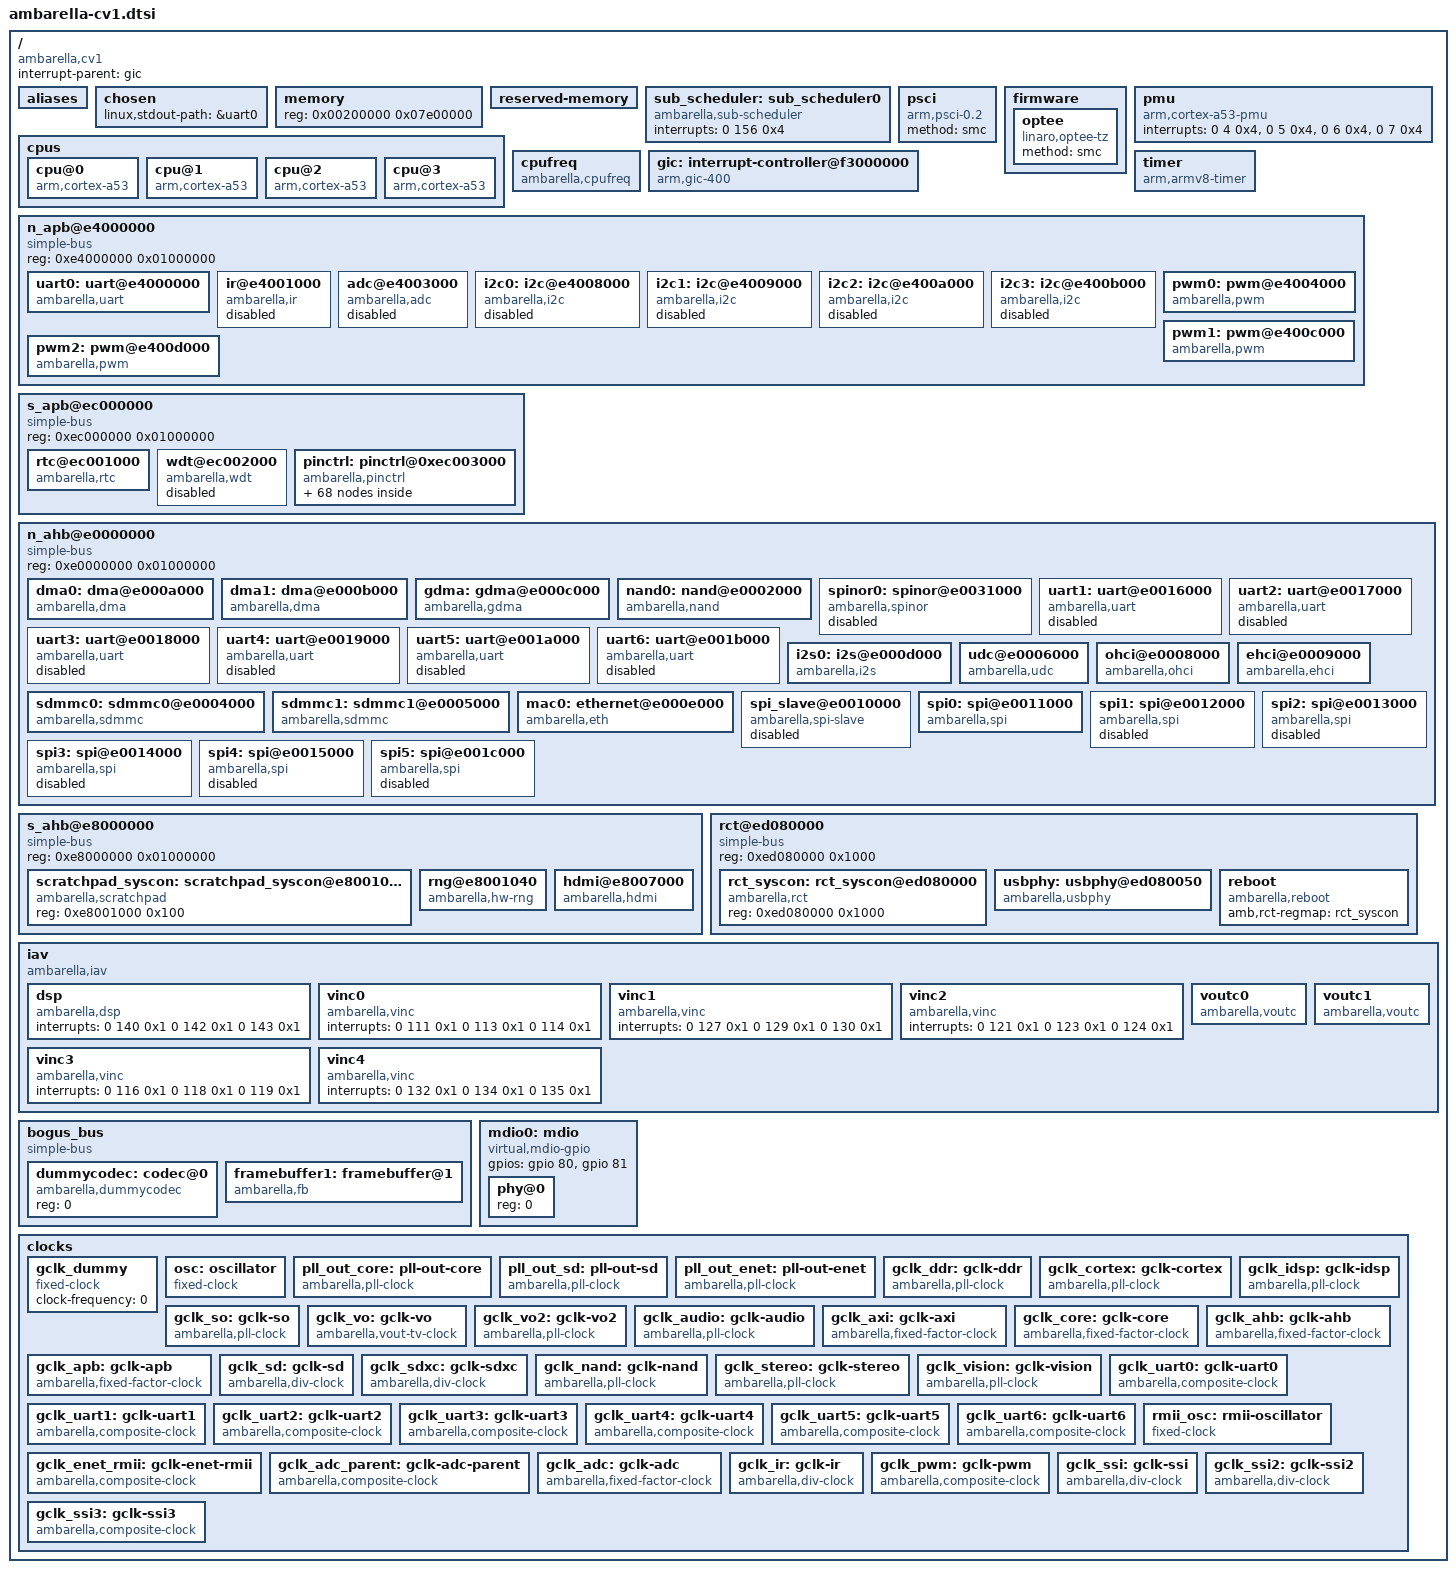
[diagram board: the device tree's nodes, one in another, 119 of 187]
/*
 * Copyright (C) 2013 Ambarella,Inc. - http://www.ambarella.com/
 * Author: Cao Rongrong <rrcao@ambarella.com>
 *
 * This program is free software; you can redistribute it and/or modify
 * it under the terms of the GNU General Public License version 2 as
 * published by the Free Software Foundation.
 */

/ {
	compatible = "ambarella,cv1";
	interrupt-parent = <&gic>;
	#address-cells = <1>;
	#size-cells = <1>;

	aliases {
		serial0 = &uart0;
		serial1 = &uart1;
		serial2 = &uart2;
		serial3 = &uart3;
		serial4 = &uart4;
		serial5 = &uart5;
		serial6 = &uart6;
		nand = &nand0;
		sd0 = &sdmmc0;
		spinor = &spinor0;
		i2c0 = &i2c0;
		i2c1 = &i2c1;
		i2c2 = &i2c2;
		i2c3 = &i2c3;
		spi0 = &spi0;
		spi1 = &spi1;
		spi2 = &spi2;
		ethernet0 = &mac0;
		mdio-gpio0 = &mdio0;
	};

	chosen {
		linux,stdout-path = &uart0;
	};

	/*
	 * the memory node will be overwritten in Amboot,
	 * here is just the default value.
	 */
	memory {
		device_type = "memory";
		reg = <0x00200000 0x07e00000>; /* 126M */
	};

	reserved-memory {
		#address-cells = <1>;
		#size-cells = <1>;
		ranges;
	};

	sub_scheduler: sub_scheduler0 {
		compatible = "ambarella,sub-scheduler";
		interrupts = <0 156 0x4>;
	};

	psci {
		compatible = "arm,psci-0.2";
		method = "smc";
	};

	firmware {
		optee {
			compatible = "linaro,optee-tz";
			method = "smc";
		};
	};

	pmu {
		compatible = "arm,cortex-a53-pmu";
		interrupts = <0 4 0x4>,
			     <0 5 0x4>,
			     <0 6 0x4>,
			     <0 7 0x4>;
	};

	cpus {
		#address-cells = <1>;
		#size-cells = <0>;
		cpu@0 {
			compatible = "arm,cortex-a53", "arm,armv8";
			device_type = "cpu";
			reg = <0x0>;
			enable-method = "psci";
		};

		cpu@1 {
			compatible = "arm,cortex-a53", "arm,armv8";
			device_type = "cpu";
			reg = <0x1>;
			enable-method = "psci";
		};

		cpu@2 {
			compatible = "arm,cortex-a53", "arm,armv8";
			device_type = "cpu";
			reg = <0x2>;
			enable-method = "psci";
		};

		cpu@3 {
			compatible = "arm,cortex-a53", "arm,armv8";
			device_type = "cpu";
			reg = <0x3>;
			enable-method = "psci";
		};
	};

	cpufreq {
		compatible = "ambarella,cpufreq";
		/*
		 * Config effective clocks. '%KHZ'
		 *
		 * 0 - cortex.
		 * 1 - pll_out_core.
		 * 2 - cortex and pll_out_core.
		 */
		cpufreq-effective-clock = <0>;			/* default 'cortex' */
		clocks = <&gclk_cortex &pll_out_core>;
		clock-names = "cortex_clk", "core_clk";
		clocks-frequency-cortex-core =
			<1008000  672000>,
			< 816000  504000>,
			< 600000  336000>;
	};

	gic: interrupt-controller@f3000000 {
		compatible = "arm,gic-400";
		#interrupt-cells = <3>;
		#address-cells = <0>;
		interrupt-controller;
		reg = <0xf3001000 0x1000>,	/* GIC Dist */
		      <0xf3002000 0x2000>,	/* GIC CPU */
		      /* following are not used if no virtulization */
		      <0xf3004000 0x2000>,	/* GIC VCPU Control */
		      <0xf3006000 0x2000>;	/* GIC VCPU */
		interrupts = <1 9 0xf04>;	/* GIC Maintenence IRQ */
	};

	timer {
		compatible = "arm,armv8-timer";
		interrupts = <1 13 0xf08>,	/* Secure Phys IRQ */
			     <1 14 0xf08>,	/* Non-secure Phys IRQ */
			     <1 11 0xf08>,	/* Virt IRQ */
			     <1 10 0xf08>;	/* Hyp IRQ */
	};

	n_apb@e4000000 { /* Non-Secure APB */
		compatible = "simple-bus";
		#address-cells = <1>;
		#size-cells = <1>;
		reg = <0xe4000000 0x01000000>;
		ranges;

		uart0: uart@e4000000 {
			compatible = "ambarella,uart";
			reg = <0xe4000000 0x1000>;
			interrupts = <0 22 0x4>;
			pinctrl-names = "default";
			pinctrl-0 = <&uart0_pins>;
			clocks = <&gclk_uart0>;
			status = "ok";
		};

		ir@e4001000 {
			compatible = "ambarella,ir";
			reg = <0xe4001000 0x1000>;
			interrupts = <0 21 0x4>;
			pinctrl-names = "default";
			pinctrl-0 = <&ir_pins>;
			clocks = <&gclk_ir>;
			status = "disabled";
		};

		adc@e4003000 {
			compatible = "ambarella,adc";
			#io-channel-cells = <1>;
			reg = <0xe4003000 0x1000>;
			interrupts = <0 14 0x4>;
			clock-frequency = <3000000>;
			clocks = <&gclk_adc>;
			amb,rct-regmap = <&rct_syscon>;
			amb,scaler-1v8 = <0x01>;
			amb,t2v-channel = <2>;
			status = "disabled";
		};

		i2c0: i2c@e4008000 {
			compatible = "ambarella,i2c";
			#address-cells = <1>;
			#size-cells = <0>;
			reg = <0xe4008000 0x1000>;
			interrupts = <0 16 0x4>;
			pinctrl-names = "default";
			pinctrl-0 = <&i2c0_pins_a>;
			clocks = <&gclk_apb>;
			clock-frequency = <100000>;
			amb,i2c-class = <0x81>;
			status = "disabled";
		};

		i2c1: i2c@e4009000 {
			compatible = "ambarella,i2c";
			#address-cells = <1>;
			#size-cells = <0>;
			reg = <0xe4009000 0x1000>;
			interrupts = <0 17 0x4>;
			pinctrl-names = "default";
			pinctrl-0 = <&i2c1_pins_a>;
			clocks = <&gclk_apb>;
			clock-frequency = <100000>;
			amb,i2c-class = <0x08>;
			status = "disabled";
		};

		i2c2: i2c@e400a000 {
			compatible = "ambarella,i2c";
			#address-cells = <1>;
			#size-cells = <0>;
			reg = <0xe400a000 0x1000>;
			interrupts = <0 18 0x4>;
			clocks = <&gclk_apb>;
			pinctrl-names = "default";
			pinctrl-0 = <&i2c2_pins_a>;
			clock-frequency = <100000>;
			amb,i2c-class = <0x81>;
			status = "disabled";
		};

		i2c3: i2c@e400b000 {
			compatible = "ambarella,i2c";
			#address-cells = <1>;
			#size-cells = <0>;
			reg = <0xe400b000 0x1000>;
			interrupts = <0 19 0x4>;
			clocks = <&gclk_apb>;
			pinctrl-names = "default";
			pinctrl-0 = <&i2c3_pins_a>;
			clock-frequency = <100000>;
			amb,i2c-class = <0x81>;
			status = "disabled";
		};

		pwm0: pwm@e4004000 {
			compatible = "ambarella,pwm";
			reg = <0xe4004000 0x1000>;
			clock-frequency = <2000000>;
			clocks = <&gclk_pwm>;
			#pwm-cells = <3>;
		};

		pwm1: pwm@e400c000 {
			compatible = "ambarella,pwm";
			reg = <0xe400c000 0x1000>;
			clock-frequency = <2000000>;
			clocks = <&gclk_pwm>;
			#pwm-cells = <3>;
		};

		pwm2: pwm@e400d000 {
			compatible = "ambarella,pwm";
			reg = <0xe400d000 0x1000>;
			clock-frequency = <2000000>;
			clocks = <&gclk_pwm>;
			#pwm-cells = <3>;
		};
	};

	s_apb@ec000000 { /* Secure APB */
		compatible = "simple-bus";
		#address-cells = <1>;
		#size-cells = <1>;
		reg = <0xec000000 0x01000000>;
		ranges;

		rtc@ec001000 {
			compatible = "ambarella,rtc";
			reg = <0xec001000 0x1000>;
			interrupts = <0 160 0x1>;
		};

		wdt@ec002000 {
			compatible = "ambarella,wdt";
			reg = <0xec002000 0x1000>;
			amb,rct-regmap = <&rct_syscon>;
			/* interrupts = <0 43 0x4>; */
			timeout-sec = <15>;
			status = "disabled";
		};

		pinctrl: pinctrl@0xec003000 {
			compatible = "ambarella,pinctrl", "simple-bus";
			#address-cells = <1>;
			#size-cells = <0>;
			reg = <0xec003000 0x1000>,
			      <0xec004000 0x1000>,
			      <0xec005000 0x1000>,
			      <0xec006000 0x1000>,
			      <0xec007000 0x1000>,
			      <0xec008000 0x1000>,
			      <0xec009000 0x1000>,
			      <0xec000000 0x1000>,
			      <0xec001080 0x100>,
			      <0xed080314 0x13c>;
			reg-names = "gpio0", "gpio1", "gpio2", "gpio3",
				    "gpio4", "gpio5", "gpio6","iomux",
				    "pad", "ds";
			#gpio-range-cells = <3>;

			gpio: gpio@0 {
				compatible = "ambarella,gpio";
				reg = <0>;
				/* gpio interrupts to gic */
				interrupts = <0 44 0x4>,
					     <0 45 0x4>,
					     <0 46 0x4>,
					     <0 47 0x4>,
					     <0 48 0x4>,
					     <0 49 0x4>,
					     <0 50 0x4>;
				gpio-controller;
				#gpio-cells = <2>;
				gpio-ranges = <&pinctrl 0 0 224>;
				interrupt-controller;
				#interrupt-cells = <2>;
			};

			uart0_pins: uart0@0 {
				reg = <0>;
				amb,pinmux-ids = <0x1033 0x1034>;
			};

			uart1_pins: uart1@0 {
				reg = <0>;
				amb,pinmux-ids = <0x10ba 0x10bb>;
			};

			uart1_flow_pins: uart1_flow@0 {
				reg = <0>;
				amb,pinmux-ids = <0x10bc 0x10bd>;
			};

			uart2_pins: uart2@0 {
				reg = <0>;
				amb,pinmux-ids = <0x10be 0x10bf>;
			};

			uart2_flow_pins: uart2_flow@0 {
				reg = <0>;
				amb,pinmux-ids = <0x10c0 0x10c1>;
			};

			uart3_pins: uart3@0 {
				reg = <0>;
				amb,pinmux-ids = <0x10c2 0x10c3>;
			};

			uart3_flow_pins: uart3_flow@0 {
				reg = <0>;
				amb,pinmux-ids = <0x10c4 0x10c5>;
			};

			uart4_pins: uart4@0 {
				reg = <0>;
				amb,pinmux-ids = <0x10c6 0x10c7>;
			};

			uart4_flow_pins: uart4_flow@0 {
				reg = <0>;
				amb,pinmux-ids = <0x10c8 0x10c9>;
			};

			uart5_pins: uart5@0 {
				reg = <0>;
				amb,pinmux-ids = <0x10ca 0x10cc>;
			};

			uart5_flow_pins: uart5_flow@0 {
				reg = <0>;
				amb,pinmux-ids = <0x10ce 0x10d0>;
			};

			uart6_pins: uart6@0 {
				reg = <0>;
				amb,pinmux-ids = <0x10cb 0x10cd>;
			};

			uart6_flow_pins: uart6_flow@0 {
				reg = <0>;
				amb,pinmux-ids = <0x10cf 0x10d1>;
			};

			nand0_pins: nand0@0 {
				reg = <0>;
				amb,pinmux-ids = <0x2056 0x2057 0x2058 0x205d
						  0x205e 0x205f 0x2060 0x2061
						  0x2062 0x2063 0x2064 0x2065
						  0x2066 0x2067 0x2068>;
			};

			snand0_pins: snand0@0 {
				reg = <0>;
				amb,pinmux-ids = <0x405d 0x405e 0x4064 0x4065
						  0x4066 0x4067>;
			};

			spinor0_pins: spinor0@0 {
				reg = <0>;
				amb,pinmux-ids = <0x3057 0x3058 0x305d 0x305e
						  0x305f 0x3060 0x3061 0x3062
						  0x3063 0x3064 0x3065 0x3066
						  0x3067>;
			};

			sdmmc0_cd_pin: sdmmc0_cd@0 {
				reg = <0>;
				amb,pinmux-ids = <0x205b>;
			};

			sdmmc0_wp_pin: sdmmc0_wp@0 {
				reg = <0>;
				amb,pinmux-ids = <0x205c>;
			};

			sdmmc0_reset_pin: sdmmc0_reset@0 {
				reg = <0>;
				amb,pinmux-ids = <0x207d>;
			};

			sdmmc0_pins_1bit: sdmmc0@0 {
				reg = <0>;
				amb,pinmux-ids = <0x2059 0x205a 0x2069>;
			};

			sdmmc0_pins_4bit: sdmmc0@1 {
				reg = <1>;
				amb,pinmux-ids = <0x2059 0x205a 0x2069 0x206a
						  0x206b 0x206c>;
			};

			sdmmc0_pins_8bit: sdmmc0@2 {
				reg = <2>;
				amb,pinmux-ids = <0x2059 0x205a 0x2069 0x206a
						  0x206b 0x206c 0x206d 0x206e
						  0x206f 0x2070>;
			};

			sdmmc1_cd_pin: sdmmc1_cd@0 {
				reg = <0>;
				amb,pinmux-ids = <0x2077>;
			};

			sdmmc1_wp_pin: sdmmc1_wp@0 {
				reg = <0>;
				amb,pinmux-ids = <0x2078>;
			};

			sdmmc1_reset_pin: sdmmc1_reset@0 {
				reg = <0>;
				amb,pinmux-ids = <0x207e>;
			};

			sdmmc1_pins_1bit: sdmmc1@0 {
				reg = <0>;
				amb,pinmux-ids = <0x2071 0x2072 0x2073>;
			};

			sdmmc1_pins_4bit: sdmmc1@1 {
				reg = <1>;
				amb,pinmux-ids = <0x2071 0x2072 0x2073 0x2074
						  0x2075 0x2076>;
			};

			sdmmc1_pins_8bit: sdmmc1@2 {
				reg = <2>;
				amb,pinmux-ids = <0x2071 0x2072 0x2073 0x2074
						  0x2075 0x2076 0x2079 0x207a
						  0x207b 0x207c>;
			};

			rgmii_pins: eth0@0 {
				reg = <0>;
				amb,pinmux-ids = <0x4046 0x4047 0x4048 0x4049
						  0x404a 0x404b 0x404c 0x404d
						  0x404e 0x404f 0x4052 0x4053
						  0x4054 0x4055>;
			};

			rmii_pins: eth0@1 {
				reg = <1>;
				amb,pinmux-ids = <0x3046 0x3047 0x3048 0x304b
						  0x304c 0x304f 0x3052 0x3053
						  0x3054 0x3055>;
			};

			rgmii_mdio_pins: mdio@0 {
				reg = <0>;
				amb,pinmux-ids = <0x4050 0x4051>;
			};

			rmii_mdio_pins: mdio@1 {
				reg = <1>;
				amb,pinmux-ids = <0x3050 0x3051>;
			};

			i2c0_pins_a: i2c0@0 {
				reg = <0>;
				amb,pinmux-ids = <0x100f 0x1010>;
			};

			i2c0_pins_b: i2c0@1 {
				reg = <1>;
				amb,pinmux-ids = <0x2025 0x2026>;
			};

			i2c1_pins_a: i2c1@0 {
				reg = <0>;
				amb,pinmux-ids = <0x1011 0x1012>;
			};

			i2c1_pins_b: i2c1@1 {
				reg = <1>;
				amb,pinmux-ids = <0x2027 0x2028>;
			};

			i2c2_pins_a: i2c2@0 {
				reg = <0>;
				amb,pinmux-ids = <0x1013 0x1014>;
			};

			i2c2_pins_b: i2c2@1 {
				reg = <1>;
				amb,pinmux-ids = <0x2029 0x202a>;
			};

			i2c3_pins_a: i2c3@0 {
				reg = <0>;
				amb,pinmux-ids = <0x1015 0x1016>;
			};

			i2c3_pins_b: i2c3@1 {
				reg = <1>;
				amb,pinmux-ids = <0x202b 0x202c>;
			};

			ir_pins: ir0@0 {
				reg = <0>;
				amb,pinmux-ids = <0x1019>;
			};

			i2s0_pins: i2s0@0 {
				reg = <0>;
				amb,pinmux-ids = <0x1041 0x1042 0x1043 0x1044
						  0x1045>;
			};

			usb_host0_pins_a: uhc0@0 { /* USB0: host/device configurable */
				reg = <0>;
				amb,pinmux-ids = <0x3008 0x300a>;
			};

			usb_host0_pins_b: uhc0@1 { /* USB0: host/device configurable */
				reg = <1>;
				amb,pinmux-ids = <0x302f 0x3031>;
			};

			usb_host0_pins_c: uhc0@2 { /* USB0: host/device configurable */
				reg = <2>;
				amb,pinmux-ids = <0x5079 0x507b>;
			};

			pwm0_pins_a: pwm0@0 {
				reg = <0>;
				amb,pinmux-ids = <0x1035>;
			};

			pwm0_pins_b: pwm0@1 {
				reg = <1>;
				amb,pinmux-ids = <0x10b9>;
			};

			pwm1_pins: pwm1@0 {
				reg = <0>;
				amb,pinmux-ids = <0x3036>;
			};

			pwm2_pins: pwm2@0 {
				reg = <0>;
				amb,pinmux-ids = <0x3037>;
			};

			pwm3_pins: pwm3@0 {
				reg = <0>;
				amb,pinmux-ids = <0x3038>;
			};

			pwm4_pins: pwm4@0 {
				reg = <0>;
				amb,pinmux-ids = <0x1039>;
			};

			pwm5_pins: pwm5@0 {
				reg = <0>;
				amb,pinmux-ids = <0x103a>;
			};

			pwm6_pins: pwm6@0 {
				reg = <0>;
				amb,pinmux-ids = <0x103b>;
			};

			pwm7_pins: pwm7@0 {
				reg = <0>;
				amb,pinmux-ids = <0x103c>;
			};

			pwm8_pins: pwm8@0 {
				reg = <0>;
				amb,pinmux-ids = <0x103d>;
			};

			pwm9_pins: pwm9@0 {
				reg = <0>;
				amb,pinmux-ids = <0x103e>;
			};

			pwm10_pins: pwm10@0 {
				reg = <0>;
				amb,pinmux-ids = <0x103f>;
			};

			pwm11_pins: pwm11@0 {
				reg = <0>;
				amb,pinmux-ids = <0x1040>;
			};

			spi_slave_pins: spi_slave@0 {
				reg = <0>;
				amb,pinmux-ids = <0x102f 0x1030 0x1031 0x1032>;
			};

			spi0_pins: spi0@0 {
				reg = <0>;
				amb,pinmux-ids = <0x101a 0x101b 0x101c>;
			};

			spi1_pins_a: spi1@0 {
				reg = <0>;
				amb,pinmux-ids = <0x2000 0x2001 0x2002>;
			};

			spi1_pins_b: spi1@1 {
				reg = <1>;
				amb,pinmux-ids = <0x202f 0x2030 0x2031>;
			};

			spi1_pins_c: spi1@2 {
				reg = <2>;
				amb,pinmux-ids = <0x20ba 0x20bb 0x20bc>;
			};

			spi2_pins: spi2@0 {
				reg = <0>;
				amb,pinmux-ids = <0x101f 0x1020 0x1021>;
			};

			spi3_pins: spi3@0 {
				reg = <0>;
				amb,pinmux-ids = <0x1023 0x1024 0x1025>;
			};

			spi4_pins: spi4@0 {
				reg = <0>;
				amb,pinmux-ids = <0x1027 0x1028 0x1029>;
			};

			spi5_pins: spi5@0 {
				reg = <0>;
				amb,pinmux-ids = <0x102b 0x102c 0x102d>;
			};
		};
	};

	n_ahb@e0000000 { /* Non-Secure AHB */
		compatible = "simple-bus";
		#address-cells = <1>;
		#size-cells = <1>;
		reg = <0xe0000000 0x01000000>;
		ranges;

		dma0: dma@e000a000 {
			compatible = "ambarella,dma";
			reg = <0xe000a000 0x1000>, <0xe8001030 0x8>;
			interrupts = <0 83 0x4>;
			#dma-cells = <1>;
			dma-channels = <8>;
			dma-requests = <30>;
		};

		dma1: dma@e000b000 {
			compatible = "ambarella,dma";
			reg = <0xe000b000 0x1000>, <0xe8001038 0x8>;
			interrupts = <0 84 0x4>;
			#dma-cells = <1>;
			dma-channels = <8>;
			dma-requests = <30>;
		};

		gdma: gdma@e000c000 {
			compatible = "ambarella,gdma";
			reg = <0xe000c000 0x400>;
			interrupts = <0 70 0x1>;
		};

		nand0: nand@e0002000 {
			compatible = "ambarella,nand";
			#address-cells = <1>;
			#size-cells = <1>;
			reg = <0xe0002000 0x1000>;
			interrupts = <0 68 0x4>;	/* fio_irq */
			amb,rct-regmap = <&rct_syscon>;
			pinctrl-names = "default", "spinand";
			pinctrl-0 = <&nand0_pins>;
			pinctrl-1 = <&snand0_pins>;
			clocks = <&gclk_nand>;
			nand-on-flash-bbt;
			/* amb,soft-ecc = <1>; */
		};

		spinor0: spinor@e0031000 {
			compatible = "ambarella,spinor";
			reg = <0xe0031000 0x2ff>; /* spi nor controller */
			interrupts = <0 73 0x4>;
			pinctrl-names = "default";
			pinctrl-0 = <&spinor0_pins>;
			clocks = <&gclk_ssi3>;
			dmas = <&dma0 4>, <&dma0 5>;
			dma-names = "tx", "rx";
			max-frequency = <50000000>;
			status = "disabled";
		};

		uart1: uart@e0016000 {
			compatible = "ambarella,uart";
			reg = <0xe0016000 0x1000>;
			interrupts = <0 59 0x4>;
			pinctrl-names = "default";
			pinctrl-0 = <&uart1_pins &uart1_flow_pins>;
			clocks = <&gclk_uart1>;
			status = "disabled";
			amb,msr-used;	/* use Modem Status Register */
			amb,txdma-used;
			amb,rxdma-used;
			dmas = <&dma0 8>, <&dma0 9>;
			dma-names = "tx", "rx";
		};

		uart2: uart@e0017000 {
			compatible = "ambarella,uart";
			reg = <0xe0017000 0x1000>;
			interrupts = <0 60 0x4>;
			pinctrl-names = "default";
			pinctrl-0 = <&uart2_pins &uart2_flow_pins>;
			clocks = <&gclk_uart2>;
			amb,msr-used;	/* use Modem Status Register */
			amb,txdma-used;
			amb,rxdma-used;
			dmas = <&dma1 12>, <&dma1 13>;
			dma-names = "tx", "rx";
			status = "disabled";
		};

		uart3: uart@e0018000 {
			compatible = "ambarella,uart";
			reg = <0xe0018000 0x1000>;
			interrupts = <0 61 0x4>;
			pinctrl-names = "default";
			pinctrl-0 = <&uart3_pins &uart3_flow_pins>;
			clocks = <&gclk_uart3>;
			amb,msr-used;	/* use Modem Status Register */
			amb,txdma-used;
			amb,rxdma-used;
			dmas = <&dma1 14>, <&dma1 15>;
			dma-names = "tx", "rx";
			status = "disabled";
		};

		uart4: uart@e0019000 {
			compatible = "ambarella,uart";
			reg = <0xe0019000 0x1000>;
			interrupts = <0 62 0x4>;
			pinctrl-names = "default";
			pinctrl-0 = <&uart4_pins &uart4_flow_pins>;
			clocks = <&gclk_uart4>;
			amb,msr-used;	/* use Modem Status Register */
			amb,txdma-used;
			amb,rxdma-used;
			dmas = <&dma1 16>, <&dma1 17>;
			dma-names = "tx", "rx";
			status = "disabled";
		};

		uart5: uart@e001a000 {
			compatible = "ambarella,uart";
			reg = <0xe001a000 0x1000>;
			interrupts = <0 63 0x4>;
			pinctrl-names = "default";
			pinctrl-0 = <&uart5_pins &uart5_flow_pins>;
			clocks = <&gclk_uart5>;
			amb,msr-used;	/* use Modem Status Register */
			amb,txdma-used;
			amb,rxdma-used;
			dmas = <&dma1 18>, <&dma1 19>;
			dma-names = "tx", "rx";
			status = "disabled";
		};

		uart6: uart@e001b000 {
			compatible = "ambarella,uart";
			reg = <0xe001b000 0x1000>;
			interrupts = <0 64 0x4>;
			pinctrl-names = "default";
			pinctrl-0 = <&uart6_pins &uart6_flow_pins>;
			clocks = <&gclk_uart6>;
			amb,msr-used;	/* use Modem Status Register */
			amb,txdma-used;
			amb,rxdma-used;
			dmas = <&dma1 20>, <&dma1 21>;
			dma-names = "tx", "rx";
			status = "disabled";
		};

		i2s0: i2s@e000d000 {
			compatible = "ambarella,i2s";
			#sound-dai-cells = <0>;
			reg = <0xe000d000 0x1000>;
			pinctrl-names = "default";
			pinctrl-0 = <&i2s0_pins>;
			clocks = <&gclk_audio>;
			amb,i2s-channels = <2>;
			amb,default-mclk = <12288000>;
			dmas = <&dma0 10>, <&dma0 11>;
			dma-names = "tx", "rx";
		};

		udc@e0006000 {
			compatible = "ambarella,udc";
			reg = <0xe0006000 0x2000>;
			interrupts = <0 67 0x4>;
			amb,rct-regmap = <&rct_syscon>;
			amb,scr-regmap = <&scratchpad_syscon>;
			amb,usbphy = <&usbphy>;
		};

		ohci@e0008000 {
			compatible = "ambarella,ohci";
			reg = <0xe0008000 0x1000>;
			interrupts = <0 66 0x4>;
			amb,usbphy = <&usbphy>;
		};

		ehci@e0009000 {
			compatible = "ambarella,ehci";
			reg = <0xe0009000 0x1000>;
			interrupts = <0 65 0x4>;
			amb,usbphy = <&usbphy>;
		};

		sdmmc0: sdmmc0@e0004000 {
			compatible = "ambarella,sdmmc";
			#address-cells = <1>;
			#size-cells = <0>;
			reg = <0xe0004000 0x1000>;
			interrupts = <0 72 0x4>;
			pinctrl-names = "default";
			pinctrl-0 = <&sdmmc0_pins_8bit &sdmmc0_cd_pin &sdmmc0_wp_pin>;
			clocks = <&gclk_sd>;
			amb,rct-regmap = <&rct_syscon 0x4c0 0x4c4 0x664 0x4f0 0>;
			amb,tuning-tx-clk = <0>;
			max-frequency = <120000000>;
			bus-width = <8>;
			cap-sdio-irq;
			cap-sd-highspeed;
			cap-mmc-highspeed;
			mmc-hs200-1_8v;
		};

		sdmmc1: sdmmc1@e0005000 { /* SDXC rather than SDIO */
			compatible = "ambarella,sdmmc";
			#address-cells = <1>;
			#size-cells = <0>;
			reg = <0xe0005000 0x1000>;
			interrupts = <0 71 0x4>;
			pinctrl-names = "default";
			pinctrl-0 = <&sdmmc1_pins_8bit &sdmmc1_cd_pin &sdmmc1_wp_pin>;
			clocks = <&gclk_sdxc>;
			amb,rct-regmap = <&rct_syscon 0x4c8 0x4cc 0x668 0x4f0 16>;
			amb,tuning-tx-clk = <0>;
			max-frequency = <100000000>;
			bus-width = <8>;
			cap-sdio-irq;
			cap-sd-highspeed;
			cap-mmc-highspeed;
			mmc-hs200-1_8v;
		};

		mac0: ethernet@e000e000 {
			compatible = "ambarella,eth";
			#address-cells = <1>;
			#size-cells = <0>;
			reg = <0xe000e000 0x2000>;
			interrupts = <0 58 0x4>;
			pinctrl-names = "default";
			pinctrl-0 = <&rgmii_pins &rgmii_mdio_pins>;
			phy-mode = "rgmii";
			amb,rct-regmap = <&rct_syscon>;
			amb,scr-regmap = <&scratchpad_syscon>;
			amb,tx-ring-size = <32>;
			amb,rx-ring-size = <64>;
			amb,ipc-tx;
			amb,ipc-rx;
			amb,enhance;
			/* amb,mdio-gpio; */
			/* amb,tx-clk-invert; */
		};

		spi_slave@e0010000 {
			compatible = "ambarella,spi-slave";
			reg = <0xe0010000 0x1000>;
			interrupts = <0 80 0x4>;
			pinctrl-names = "default";
			pinctrl-0 = <&spi_slave_pins>;
			status = "disabled";
		};

		spi0: spi@e0011000 {
			compatible = "ambarella,spi";
			#address-cells = <1>;
			#size-cells = <0>;
			reg = <0xe0011000 0x1000>;
			interrupts = <0 74 0x4>;
			pinctrl-names = "default";
			pinctrl-0 = <&spi0_pins>;
			amb,clk-freq = <54000000>;
			/* amb,dma-used; */
			dmas = <&dma0 0>, <&dma0 1>;
			dma-names = "tx", "rx";
		};

		spi1: spi@e0012000 {
			compatible = "ambarella,spi";
			#address-cells = <1>;
			#size-cells = <0>;
			reg = <0xe0012000 0x1000>;
			interrupts = <0 75 0x4>;
			pinctrl-names = "default";
			pinctrl-0 = <&spi1_pins_a>;
			amb,clk-freq = <54000000>;
			/* amb,dma-used; */
			dmas = <&dma0 2>, <&dma0 3>;
			dma-names = "tx", "rx";
			status = "disabled";
		};

		spi2: spi@e0013000 {
			compatible = "ambarella,spi";
			#address-cells = <1>;
			#size-cells = <0>;
			reg = <0xe0013000 0x1000>;
			interrupts = <0 76 0x4>;
			pinctrl-names = "default";
			pinctrl-0 = <&spi2_pins>;
			amb,clk-freq = <54000000>;
			/* amb,dma-used; */
			dmas = <&dma1 22>, <&dma1 23>;
			dma-names = "tx", "rx";
			status = "disabled";
		};

		spi3: spi@e0014000 {
			compatible = "ambarella,spi";
			#address-cells = <1>;
			#size-cells = <0>;
			reg = <0xe0014000 0x1000>;
			interrupts = <0 77 0x4>;
			pinctrl-names = "default";
			pinctrl-0 = <&spi3_pins>;
			amb,clk-freq = <54000000>;
			/* amb,dma-used; */
			dmas = <&dma1 24>, <&dma1 25>;
			dma-names = "tx", "rx";
			status = "disabled";
		};

		spi4: spi@e0015000 {
			compatible = "ambarella,spi";
			#address-cells = <1>;
			#size-cells = <0>;
			reg = <0xe0015000 0x1000>;
			interrupts = <0 78 0x4>;
			pinctrl-names = "default";
			pinctrl-0 = <&spi4_pins>;
			amb,clk-freq = <54000000>;
			/* amb,dma-used; */
			dmas = <&dma1 26>, <&dma1 27>;
			dma-names = "tx", "rx";
			status = "disabled";
		};

		spi5: spi@e001c000 {
			compatible = "ambarella,spi";
			#address-cells = <1>;
			#size-cells = <0>;
			reg = <0xe001c000 0x1000>;
			interrupts = <0 79 0x4>;
			pinctrl-names = "default";
			pinctrl-0 = <&spi5_pins>;
			amb,clk-freq = <54000000>;
			/* amb,dma-used; */
			dmas = <&dma1 28>, <&dma1 29>;
			dma-names = "tx", "rx";
			status = "disabled";
		};
	};

	s_ahb@e8000000 { /* Secure AHB */
		compatible = "simple-bus";
		#address-cells = <1>;
		#size-cells = <1>;
		reg = <0xe8000000 0x01000000>;
		ranges;

		scratchpad_syscon: scratchpad_syscon@e8001000 {
			compatible = "ambarella,scratchpad", "syscon";
			reg = <0xe8001000 0x100>;
		};

		rng@e8001040 {
			compatible = "ambarella,hw-rng";
			reg = <0xe8001040 0x14>;
			amb,rct-regmap = <&rct_syscon>;
		};

		hdmi@e8007000 {
			compatible = "ambarella,hdmi";
			reg = <0xe8007000 0x1000>;
			interrupts = <0 85 0x4>;
			interrupt-names = "hdmi";
			amb,hdmiphy = <0xed080010>;
			amb,hdmi-version = <20>;
		};
	};

	rct@ed080000 {
		compatible = "simple-bus";
		#address-cells = <1>;
		#size-cells = <1>;
		reg = <0xed080000 0x1000>;
		ranges;

		rct_syscon: rct_syscon@ed080000 {
			compatible = "ambarella,rct", "syscon";
			reg = <0xed080000 0x1000>;
		};

		usbphy: usbphy@ed080050 {
			compatible = "ambarella,usbphy";
			reg = <0xed080050 0x4 0xe800100c 0x4 0xed0802c0 0x4>;
			amb,host-phy-num = <1>;
		};

		reboot {
			compatible = "ambarella,reboot";
			amb,rct-regmap = <&rct_syscon>;
		};
	};

	iav {
		compatible = "ambarella,iav";
		#address-cells = <1>;
		#size-cells = <1>;

		/* node for dsp controller */
		dsp {
			compatible = "ambarella,dsp";
			interrupts = <0 140 0x1 0 142 0x1 0 143 0x1>;
			interrupt-names = "vdsp", "vcap", "vin_pip";
		};

		/* node for vin0 controller */
		vinc0 {
			compatible = "ambarella,vinc";
			interrupts = <0 111 0x1 0 113 0x1 0 114 0x1>;
			interrupt-names = "idsp", "idsp_sof", "idsp_last_pixel";
		};

		/* node for vin1 controller */
		vinc1 {
			compatible = "ambarella,vinc";
			interrupts = <0 127 0x1 0 129 0x1 0 130 0x1>;
			interrupt-names = "idsp", "idsp_sof", "idsp_last_pixel";
		};

		/* node for vin2 controller */
		vinc2 {
			compatible = "ambarella,vinc";
			interrupts = <0 121 0x1 0 123 0x1 0 124 0x1>;
			interrupt-names = "idsp", "idsp_sof", "idsp_last_pixel";
		};

		/* node for vin3 controller */
		vinc3 {
			compatible = "ambarella,vinc";
			interrupts = <0 116 0x1 0 118 0x1 0 119 0x1>;
			interrupt-names = "idsp", "idsp_sof", "idsp_last_pixel";
		};

		/* node for vin4 controller */
		vinc4 {
			compatible = "ambarella,vinc";
			interrupts = <0 132 0x1 0 134 0x1 0 135 0x1>;
			interrupt-names = "idsp", "idsp_sof", "idsp_last_pixel";
		};

		/* node for vout0(lcd) controller */
		voutc0 {
			compatible = "ambarella,voutc";
			output-type = "digital";
			interrupts = <0 89 0x1>;
			interrupt-names = "vout0";
			rct-regmap = <&rct_syscon>;
			clocks = <&pll_out_vo2>;
		};

		/* node for vout1(tv) controller */
		voutc1 {
			compatible = "ambarella,voutc";
			output-type = "hdmi", "cvbs";
			interrupts = <0 88 0x1>;
			interrupt-names = "vout1";
			rct-regmap = <&rct_syscon>;
			clocks = <&pll_out_hdmi>;
		};

	};

	bogus_bus {
		compatible = "simple-bus";
		#address-cells = <1>;
		#size-cells = <0>;

		dummycodec: codec@0 {
			compatible = "ambarella,dummycodec";
			reg = <0>;
		};

		/*
		framebuffer0: framebuffer@0 {
			compatible = "ambarella,fb";
			reg = <0>;
			amb,vout-id = <0>;
			amb,format = "rgb565";
		};
		*/

		framebuffer1: framebuffer@1 {
			compatible = "ambarella,fb";
			reg = <1>;
			amb,vout-id = <1>;
			amb,format = "rgb565";
		};
	};

	mdio0: mdio {
		compatible = "virtual,mdio-gpio";
		#address-cells = <1>;
		#size-cells = <0>;
		gpios = <&gpio 80 0
			 &gpio 81 0>;

		phy@0{
			reg = <0>;
		};
	};

	clocks {
		#address-cells = <1>;
		#size-cells = <1>;
		ranges;

		/*
		 * This is a dummy clock, to be used as placeholder on other
		 * mux clocks when corresponding bits in register don't represent
		 * real parent clock.
		 */
		gclk_dummy: gclk_dummy {
			#clock-cells = <0>;
			compatible = "fixed-clock";
			clock-frequency = <0>;
		};

		/*
		 * Fixed 24MHz oscillator inputs to SoC
		 */
		osc: oscillator {
			compatible = "fixed-clock";
			#clock-cells = <0>;
			clock-frequency = <24000000>;
			clock-output-names = "osc";
		};

		pll_out_core: pll-out-core {
			#clock-cells = <0>;
			compatible = "ambarella,pll-clock";
			reg = <0xed080000 4>,
			      <0xed080004 4>,
			      <0xed080100 4>,
			      <0xed080104 4>,
			      <0x00000000 0>,
			      <0x00000000 0>;
			clocks = <&osc>;
			clock-output-names = "pll_out_core";
		};

		pll_out_sd: pll-out-sd {
			#clock-cells = <0>;
			compatible = "ambarella,pll-clock";
			reg = <0xed0804ac 4>,
			      <0xed0804b0 4>,
			      <0xed0804b4 4>,
			      <0xed0804b8 4>,
			      <0x00000000 0>,
			      <0x00000000 0>;
			clocks = <&osc>;
			clock-output-names = "pll_out_sd";
		};

		pll_out_enet: pll-out-enet {
			#clock-cells = <0>;
			compatible = "ambarella,pll-clock";
			reg = <0xed080520 4>,
			      <0xed080524 4>,
			      <0xed080528 4>,
			      <0xed08052c 4>,
			      <0x00000000 0>,
			      <0x00000000 0>;
			clocks = <&osc>;
			clock-output-names = "pll_out_enet";
		};

		gclk_ddr: gclk-ddr {
			#clock-cells = <0>;
			compatible = "ambarella,pll-clock";
			reg = <0xed0800dc 4>,
			      <0xed0800e0 4>,
			      <0xed080110 4>,
			      <0xed080114 4>,
			      <0x00000000 0>,
			      <0x00000000 0>;
			clocks = <&osc>;
			clock-output-names = "gclk_ddr";
			amb,fix-divider = <2>;
		};

		gclk_cortex: gclk-cortex {
			#clock-cells = <0>;
			compatible = "ambarella,pll-clock";
			reg = <0xed080264 4>,
			      <0xed080268 4>,
			      <0xed08026c 4>,
			      <0xed080270 4>,
			      <0x00000000 0>,
			      <0x00000000 0>;
			clocks = <&osc>;
			clock-output-names = "gclk_cortex";
		};

		gclk_idsp: gclk-idsp {
			#clock-cells = <0>;
			compatible = "ambarella,pll-clock";
			reg = <0xed0800e4 4>,
			      <0xed0800e8 4>,
			      <0xed080108 4>,
			      <0xed08010c 4>,
			      <0x00000000 0>,
			      <0xed0801f4 4>;
			clocks = <&osc>;
			clock-output-names = "gclk_idsp";
			amb,extra-post-scaler;
		};

		gclk_so: gclk-so {
			#clock-cells = <0>;
			compatible = "ambarella,pll-clock";
			reg = <0xed080024 4>,
			      <0xed080028 4>,
			      <0xed08011c 4>,
			      <0xed080120 4>,
			      <0xed08004c 4>,
			      <0xed080030 4>;
			clocks = <&osc>;
			clock-output-names = "gclk_so";
			assigned-clocks = <&gclk_so>;
			assigned-clock-rates = <24000000>;
			amb,extra-pre-scaler;
			amb,extra-post-scaler;
			amb,frac-mode;
			amb,frac-nega;
		};

		gclk_vo: gclk-vo { /* for tv */
			#clock-cells = <0>;
			compatible = "ambarella,vout-tv-clock";
			reg = <0xed080164 4>,
			      <0xed080168 4>,
			      <0xed080150 4>,
			      <0xed080154 4>,
			      <0xed080170 4>,
			      <0xed080008 4>,
			      <0xed0806bc 4>;
			clocks = <&osc>;
			clock-output-names = "gclk_vo";
			assigned-clocks = <&gclk_vo>;
			assigned-clock-rates = <24000000>;
			amb,extra-pre-scaler;
			amb,frac-mode;
			amb,frac-nega;
			amb,fix-divider = <10>;
			amb,ctrl2-val = <0x3f700900>;
			amb,ctrl3-val = <0x00068306>;
			amb,min-vco = <2500>; /* in MHz */
		};

		gclk_vo2: gclk-vo2 { /* for lcd */
			#clock-cells = <0>;
			compatible = "ambarella,pll-clock";
			reg = <0xed0800c0 4>,
			      <0xed0800c4 4>,
			      <0xed08013c 4>,
			      <0xed080140 4>,
			      <0xed0800c8 4>,
			      <0xed0800cc 4>;
			clocks = <&osc>;
			clock-output-names = "gclk_vo2";
			assigned-clocks = <&gclk_vo2>;
			assigned-clock-rates = <24000000>;
			amb,extra-pre-scaler;
			amb,extra-post-scaler;
			amb,frac-mode;
			amb,frac-nega;
		};

		gclk_audio: gclk-audio {
			#clock-cells = <0>;
			compatible = "ambarella,pll-clock";
			reg = <0xed080054 4>,
			      <0xed080058 4>,
			      <0xed080124 4>,
			      <0xed08012c 4>,
			      <0xed080060 4>,
			      <0xed08005c 4>;
			clocks = <&osc>;
			clock-output-names = "gclk_audio";
			assigned-clocks = <&gclk_audio>;
			assigned-clock-rates = <12288000>;
			amb,extra-pre-scaler;
			amb,extra-post-scaler;
			amb,frac-mode;
			amb,frac-nega;
		};

		gclk_axi: gclk-axi {
			#clock-cells = <0>;
			compatible = "ambarella,fixed-factor-clock";
			clocks = <&gclk_cortex>;
			clock-output-names = "gclk_axi";
			clock-mult = <1>;
			clock-div = <3>;
		};

		gclk_core: gclk-core {
			#clock-cells = <0>;
			compatible = "ambarella,fixed-factor-clock";
			clocks = <&pll_out_core>;
			clock-output-names = "gclk_core";
			clock-mult = <1>;
			clock-div = <1>;
		};

		gclk_ahb: gclk-ahb {
			#clock-cells = <0>;
			compatible = "ambarella,fixed-factor-clock";
			clocks = <&gclk_core>;
			clock-output-names = "gclk_ahb";
			clock-mult = <1>;
			clock-div = <2>;
		};

		gclk_apb: gclk-apb {
			#clock-cells = <0>;
			compatible = "ambarella,fixed-factor-clock";
			clocks = <&gclk_ahb>;
			clock-output-names = "gclk_apb";
			clock-mult = <1>;
			clock-div = <2>;
		};

		gclk_sd: gclk-sd {
			#clock-cells = <0>;
			compatible = "ambarella,div-clock";
			reg = <0xed08000c 4>;
			clocks = <&pll_out_sd>;
			clock-output-names = "gclk_sd";
			amb,div-width = <16>;
			amb,div-shift = <0>;
		};

		gclk_sdxc: gclk-sdxc {
			#clock-cells = <0>;
			compatible = "ambarella,div-clock";
			reg = <0xed080434 4>;
			clocks = <&pll_out_sd>;
			clock-output-names = "gclk_sdxc";
			amb,div-width = <16>;
			amb,div-shift = <0>;
		};

		gclk_nand: gclk-nand {
			#clock-cells = <0>;
			compatible = "ambarella,pll-clock";
			reg = <0xed0806f8 4>,
			      <0xed0806fc 4>,
			      <0xed080700 4>,
			      <0xed080704 4>,
			      <0x00000000 0>,
			      <0x00000000 0>;
			clocks = <&osc>;
			clock-output-names = "gclk_nand";
		};

		gclk_stereo: gclk-stereo {
			#clock-cells = <0>;
			compatible = "ambarella,pll-clock";
			reg = <0xed0806d0 4>,
			      <0xed0806d4 4>,
			      <0xed0806d8 4>,
			      <0xed0806dc 4>,
			      <0x00000000 0>,
			      <0x00000000 0>;
			clocks = <&osc>;
			clock-output-names = "gclk_stereo";
		};

		gclk_vision: gclk-vision {
			#clock-cells = <0>;
			compatible = "ambarella,pll-clock";
			reg = <0xed0806e4 4>,
			      <0xed0806e8 4>,
			      <0xed0806ec 4>,
			      <0xed0806f0 4>,
			      <0x00000000 0>,
			      <0x00000000 0>;
			clocks = <&osc>;
			clock-output-names = "gclk_vision";
			assigned-clocks = <&gclk_vision>;
			assigned-clock-rates = <1008000000>;
		};

		gclk_uart0: gclk-uart0 {
			#clock-cells = <0>;
			compatible = "ambarella,composite-clock";
			reg = <0xed080038 4>, <0xed0801c8 4>;
			clocks = <&osc>, <&gclk_core>, <&pll_out_enet>, <&pll_out_sd>;
			clock-output-names = "gclk_uart0";
			assigned-clocks = <&gclk_uart0>;
			assigned-clock-parents = <&osc>;
			assigned-clock-rates = <24000000>;
			amb,div-width = <24>;
			amb,div-shift = <0>;
		};

		gclk_uart1: gclk-uart1 {
			#clock-cells = <0>;
			compatible = "ambarella,composite-clock";
			reg = <0xed080714 4>, <0xed08072c 4>;
			clocks = <&osc>, <&gclk_core>, <&pll_out_enet>, <&pll_out_sd>;
			clock-output-names = "gclk_uart1";
			assigned-clocks = <&gclk_uart1>;
			assigned-clock-parents = <&osc>;
			assigned-clock-rates = <24000000>;
			amb,div-width = <24>;
			amb,div-shift = <0>;
		};

		gclk_uart2: gclk-uart2 {
			#clock-cells = <0>;
			compatible = "ambarella,composite-clock";
			reg = <0xed080718 4>, <0xed080730 4>;
			clocks = <&osc>, <&gclk_core>, <&pll_out_enet>, <&pll_out_sd>;
			clock-output-names = "gclk_uart2";
			assigned-clocks = <&gclk_uart2>;
			assigned-clock-parents = <&osc>;
			assigned-clock-rates = <24000000>;
			amb,div-width = <24>;
			amb,div-shift = <0>;
		};

		gclk_uart3: gclk-uart3 {
			#clock-cells = <0>;
			compatible = "ambarella,composite-clock";
			reg = <0xed08071c 4>, <0xed080734 4>;
			clocks = <&osc>, <&gclk_core>, <&pll_out_enet>, <&pll_out_sd>;
			clock-output-names = "gclk_uart3";
			assigned-clocks = <&gclk_uart3>;
			assigned-clock-parents = <&osc>;
			assigned-clock-rates = <24000000>;
			amb,div-width = <24>;
			amb,div-shift = <0>;
		};

		gclk_uart4: gclk-uart4 {
			#clock-cells = <0>;
			compatible = "ambarella,composite-clock";
			reg = <0xed080720 4>, <0xed080738 4>;
			clocks = <&osc>, <&gclk_core>, <&pll_out_enet>, <&pll_out_sd>;
			clock-output-names = "gclk_uart4";
			assigned-clocks = <&gclk_uart4>;
			assigned-clock-parents = <&osc>;
			assigned-clock-rates = <24000000>;
			amb,div-width = <24>;
			amb,div-shift = <0>;
		};

		gclk_uart5: gclk-uart5 {
			#clock-cells = <0>;
			compatible = "ambarella,composite-clock";
			reg = <0xed080724 4>, <0xed08073c 4>;
			clocks = <&osc>, <&gclk_core>, <&pll_out_enet>, <&pll_out_sd>;
			clock-output-names = "gclk_uart5";
			assigned-clocks = <&gclk_uart5>;
			assigned-clock-parents = <&osc>;
			assigned-clock-rates = <24000000>;
			amb,div-width = <24>;
			amb,div-shift = <0>;
		};

		gclk_uart6: gclk-uart6 {
			#clock-cells = <0>;
			compatible = "ambarella,composite-clock";
			reg = <0xed080728 4>, <0xed080740 4>;
			clocks = <&osc>, <&gclk_core>, <&pll_out_enet>, <&pll_out_sd>;
			clock-output-names = "gclk_uart6";
			assigned-clocks = <&gclk_uart6>;
			assigned-clock-parents = <&osc>;
			assigned-clock-rates = <24000000>;
			amb,div-width = <24>;
			amb,div-shift = <0>;
		};

		rmii_osc: rmii-oscillator {
			compatible = "fixed-clock";
			#clock-cells = <0>;
			clock-frequency = <25000000>;
			clock-output-names = "rmii_osc";
		};

		gclk_enet_rmii: gclk-enet-rmii {
			#clock-cells = <0>;
			compatible = "ambarella,composite-clock";
			reg = <0xed080534 4>, <0xed0806b8 4>;
			clocks = <&rmii_osc>, <&pll_out_enet>;
			amb,div-width = <4>;
			amb,div-shift = <4>;
			amb,div-plus;
		};

		gclk_adc_parent: gclk-adc-parent {
			#clock-cells = <0>;
			compatible = "ambarella,composite-clock";
			reg = <0xed08009c 4>, <0xed0801d0 4>;
			clocks = <&osc>, <&gclk_stereo>, <&gclk_nand>;
			clock-output-names = "gclk_adc_parent";
			amb,div-width = <16>;
			amb,div-shift = <0>;
		};

		gclk_adc: gclk-adc {
			#clock-cells = <0>;
			compatible = "ambarella,fixed-factor-clock";
			clocks = <&gclk_adc_parent>;
			clock-output-names = "gclk_adc";
			clock-mult = <1>;
			clock-div = <2>;
		};

		gclk_ir: gclk-ir {
			#clock-cells = <0>;
			compatible = "ambarella,div-clock";
			reg = <0xed080044 4>;
			clocks = <&osc>;
			clock-output-names = "gclk_ir";
			amb,div-width = <24>;
			amb,div-shift = <0>;
		};

		gclk_pwm: gclk-pwm {
			#clock-cells = <0>;
			compatible = "ambarella,composite-clock";
			reg = <0xed080084 4>, <0xed0801c4 4>;
			clocks = <&gclk_apb>, <&gclk_cortex>, <&pll_out_enet>, <&osc>;
			clock-output-names = "gclk_pwm";
			assigned-clocks = <&gclk_pwm>;
			assigned-clock-parents = <&pll_out_enet>;
			amb,div-width = <24>;
			amb,div-shift = <0>;
		};

		gclk_ssi: gclk-ssi { /* for SSI master */
			#clock-cells = <0>;
			compatible = "ambarella,div-clock";
			reg = <0xed08003c 4>;
			clocks = <&gclk_core>;
			clock-output-names = "gclk_ssi";
			amb,div-width = <24>;
			amb,div-shift = <0>;
		};

		gclk_ssi2: gclk-ssi2 { /* for SSI slave */
			#clock-cells = <0>;
			compatible = "ambarella,div-clock";
			reg = <0xed0800ec 4>;
			clocks = <&gclk_core>;
			clock-output-names = "gclk_ssi2";
			amb,div-width = <24>;
			amb,div-shift = <0>;
		};

		gclk_ssi3: gclk-ssi3 {
			#clock-cells = <0>;
			compatible = "ambarella,composite-clock";
			reg = <0xed080518 4>, <0xed08051c 4>;
			clocks = <&pll_out_enet>, <&gclk_core>, <&gclk_ssi>, <&osc>;
			clock-output-names = "gclk_ssi3";
			amb,div-width = <24>;
			amb,div-shift = <0>;
		};
	};
};
